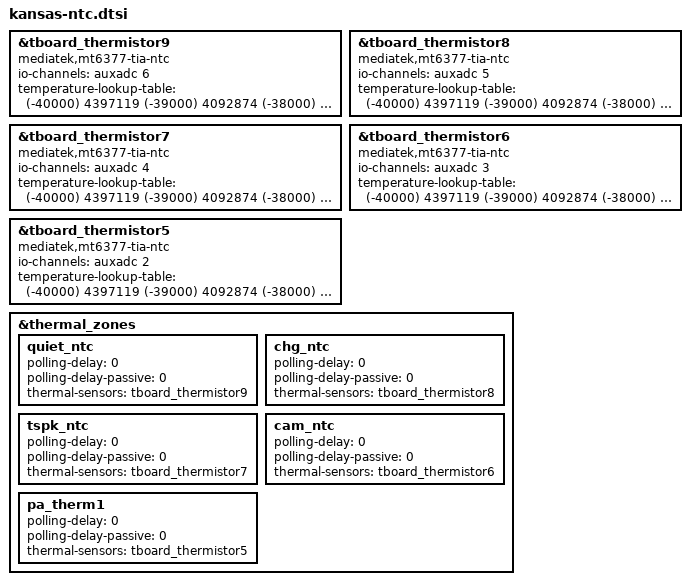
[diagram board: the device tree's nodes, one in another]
/*[TN.NJDC] ntc overlay file.start*/
&tboard_thermistor9 {
	compatible = "mediatek,mt6377-tia-ntc";
	io-channels = <&auxadc 6>;
	io-channel-names = "QUIET_NTC";
	#thermal-sensor-cells = <0>;
	temperature-lookup-table = <
		(-40000) 4397119
		(-39000) 4092874
		(-38000) 3811717
		(-37000) 3551749
		(-36000) 3311236
		(-35000) 3088599
		(-34000) 2882396
		(-33000) 2691310
		(-32000) 2514137
		(-31000) 2349778
		(-30000) 2197225
		(-29000) 2055558
		(-28000) 1923932
		(-27000) 1801573
		(-26000) 1687773
		(-25000) 1581881
		(-24000) 1483100
		(-23000) 1391113
		(-22000) 1305413
		(-21000) 1225531
		(-20000) 1151037
		(-19000) 1081535
		(-18000) 1016661
		(-17000) 956080
		(-16000) 899481
		(-15000) 846579
		(-14000) 797111
		(-13000) 750834
		(-12000) 707524
		(-11000) 666972
		(-10000) 628988
		(-9000) 593342
		(-8000) 559931
		(-7000) 528602
		(-6000) 499212
		(-5000) 471632
		(-4000) 445772
		(-3000) 421480
		(-2000) 398652
		(-1000) 377193
		0 357012
		1000 338006
		2000 320122
		3000 303287
		4000 287434
		5000 272500
		6000 258426
		7000 245160
		8000 232649
		9000 220847
		10000 209710
		11000 199196
		12000 189268
		13000 179890
		14000 171027
		15000 162651
		16000 154726
		17000 147232
		18000 140142
		19000 133432
		20000 127080
		21000 121066
		22000 115368
		23000 109970
		24000 104852
		25000 100000
		26000 95398
		27000 91032
		28000 86889
		29000 82956
		30000 79222
		31000 75675
		32000 72306
		33000 69104
		34000 66061
		35000 63167
		36000 60415
		37000 57797
		38000 55306
		39000 52934
		40000 50677
		41000 48528
		42000 46482
		43000 44533
		44000 42675
		45000 40904
		46000 39213
		47000 37601
		48000 36063
		49000 34595
		50000 33195
		51000 31859
		52000 30584
		53000 29366
		54000 28203
		55000 27091
		56000 26028
		57000 25013
		58000 24042
		59000 23113
		60000 22224
		61000 21374
		62000 20560
		63000 19782
		64000 19036
		65000 18322
		66000 17640
		67000 16986
		68000 16360
		69000 15759
		70000 15184
		71000 14631
		72000 14100
		73000 13591
		74000 13103
		75000 12635
		76000 12187
		77000 11756
		78000 11343
		79000 10946
		80000 10565
		81000 10199
		82000 9847
		83000 9509
		84000 9184
		85000 8872
		86000 8572
		87000 8283
		88000 8005
		89000 7738
		90000 7481
		91000 7234
		92000 6997
		93000 6769
		94000 6548
		95000 6337
		96000 6132
		97000 5934
		98000 5744
		99000 5561
		100000 5384
		101000 5214
		102000 5051
		103000 4893
		104000 4741
		105000 4594
		106000 4453
		107000 4316
		108000 4184
		109000 4057
		110000 3934
		111000 3816
		112000 3701
		113000 3591
		114000 3484
		115000 3380
		116000 3281
		117000 3185
		118000 3093
		119000 3003
		120000 2916
		121000 2832
		122000 2751
		123000 2672
		124000 2596
		125000 2522>;
};
&tboard_thermistor8 {
	compatible = "mediatek,mt6377-tia-ntc";
	io-channels = <&auxadc 5>;
	io-channel-names = "CHG_NTC";
	#thermal-sensor-cells = <0>;
	temperature-lookup-table = <
		(-40000) 4397119
		(-39000) 4092874
		(-38000) 3811717
		(-37000) 3551749
		(-36000) 3311236
		(-35000) 3088599
		(-34000) 2882396
		(-33000) 2691310
		(-32000) 2514137
		(-31000) 2349778
		(-30000) 2197225
		(-29000) 2055558
		(-28000) 1923932
		(-27000) 1801573
		(-26000) 1687773
		(-25000) 1581881
		(-24000) 1483100
		(-23000) 1391113
		(-22000) 1305413
		(-21000) 1225531
		(-20000) 1151037
		(-19000) 1081535
		(-18000) 1016661
		(-17000) 956080
		(-16000) 899481
		(-15000) 846579
		(-14000) 797111
		(-13000) 750834
		(-12000) 707524
		(-11000) 666972
		(-10000) 628988
		(-9000) 593342
		(-8000) 559931
		(-7000) 528602
		(-6000) 499212
		(-5000) 471632
		(-4000) 445772
		(-3000) 421480
		(-2000) 398652
		(-1000) 377193
		0 357012
		1000 338006
		2000 320122
		3000 303287
		4000 287434
		5000 272500
		6000 258426
		7000 245160
		8000 232649
		9000 220847
		10000 209710
		11000 199196
		12000 189268
		13000 179890
		14000 171027
		15000 162651
		16000 154726
		17000 147232
		18000 140142
		19000 133432
		20000 127080
		21000 121066
		22000 115368
		23000 109970
		24000 104852
		25000 100000
		26000 95398
		27000 91032
		28000 86889
		29000 82956
		30000 79222
		31000 75675
		32000 72306
		33000 69104
		34000 66061
		35000 63167
		36000 60415
		37000 57797
		38000 55306
		39000 52934
		40000 50677
		41000 48528
		42000 46482
		43000 44533
		44000 42675
		45000 40904
		46000 39213
		47000 37601
		48000 36063
		49000 34595
		50000 33195
		51000 31859
		52000 30584
		53000 29366
		54000 28203
		55000 27091
		56000 26028
		57000 25013
		58000 24042
		59000 23113
		60000 22224
		61000 21374
		62000 20560
		63000 19782
		64000 19036
		65000 18322
		66000 17640
		67000 16986
		68000 16360
		69000 15759
		70000 15184
		71000 14631
		72000 14100
		73000 13591
		74000 13103
		75000 12635
		76000 12187
		77000 11756
		78000 11343
		79000 10946
		80000 10565
		81000 10199
		82000 9847
		83000 9509
		84000 9184
		85000 8872
		86000 8572
		87000 8283
		88000 8005
		89000 7738
		90000 7481
		91000 7234
		92000 6997
		93000 6769
		94000 6548
		95000 6337
		96000 6132
		97000 5934
		98000 5744
		99000 5561
		100000 5384
		101000 5214
		102000 5051
		103000 4893
		104000 4741
		105000 4594
		106000 4453
		107000 4316
		108000 4184
		109000 4057
		110000 3934
		111000 3816
		112000 3701
		113000 3591
		114000 3484
		115000 3380
		116000 3281
		117000 3185
		118000 3093
		119000 3003
		120000 2916
		121000 2832
		122000 2751
		123000 2672
		124000 2596
		125000 2522>;
};
&tboard_thermistor7 {
	compatible = "mediatek,mt6377-tia-ntc";
	io-channels = <&auxadc 4>;
	io-channel-names = "SPK_NTC";
	#thermal-sensor-cells = <0>;
	temperature-lookup-table = <
		(-40000) 4397119
		(-39000) 4092874
		(-38000) 3811717
		(-37000) 3551749
		(-36000) 3311236
		(-35000) 3088599
		(-34000) 2882396
		(-33000) 2691310
		(-32000) 2514137
		(-31000) 2349778
		(-30000) 2197225
		(-29000) 2055558
		(-28000) 1923932
		(-27000) 1801573
		(-26000) 1687773
		(-25000) 1581881
		(-24000) 1483100
		(-23000) 1391113
		(-22000) 1305413
		(-21000) 1225531
		(-20000) 1151037
		(-19000) 1081535
		(-18000) 1016661
		(-17000) 956080
		(-16000) 899481
		(-15000) 846579
		(-14000) 797111
		(-13000) 750834
		(-12000) 707524
		(-11000) 666972
		(-10000) 628988
		(-9000) 593342
		(-8000) 559931
		(-7000) 528602
		(-6000) 499212
		(-5000) 471632
		(-4000) 445772
		(-3000) 421480
		(-2000) 398652
		(-1000) 377193
		0 357012
		1000 338006
		2000 320122
		3000 303287
		4000 287434
		5000 272500
		6000 258426
		7000 245160
		8000 232649
		9000 220847
		10000 209710
		11000 199196
		12000 189268
		13000 179890
		14000 171027
		15000 162651
		16000 154726
		17000 147232
		18000 140142
		19000 133432
		20000 127080
		21000 121066
		22000 115368
		23000 109970
		24000 104852
		25000 100000
		26000 95398
		27000 91032
		28000 86889
		29000 82956
		30000 79222
		31000 75675
		32000 72306
		33000 69104
		34000 66061
		35000 63167
		36000 60415
		37000 57797
		38000 55306
		39000 52934
		40000 50677
		41000 48528
		42000 46482
		43000 44533
		44000 42675
		45000 40904
		46000 39213
		47000 37601
		48000 36063
		49000 34595
		50000 33195
		51000 31859
		52000 30584
		53000 29366
		54000 28203
		55000 27091
		56000 26028
		57000 25013
		58000 24042
		59000 23113
		60000 22224
		61000 21374
		62000 20560
		63000 19782
		64000 19036
		65000 18322
		66000 17640
		67000 16986
		68000 16360
		69000 15759
		70000 15184
		71000 14631
		72000 14100
		73000 13591
		74000 13103
		75000 12635
		76000 12187
		77000 11756
		78000 11343
		79000 10946
		80000 10565
		81000 10199
		82000 9847
		83000 9509
		84000 9184
		85000 8872
		86000 8572
		87000 8283
		88000 8005
		89000 7738
		90000 7481
		91000 7234
		92000 6997
		93000 6769
		94000 6548
		95000 6337
		96000 6132
		97000 5934
		98000 5744
		99000 5561
		100000 5384
		101000 5214
		102000 5051
		103000 4893
		104000 4741
		105000 4594
		106000 4453
		107000 4316
		108000 4184
		109000 4057
		110000 3934
		111000 3816
		112000 3701
		113000 3591
		114000 3484
		115000 3380
		116000 3281
		117000 3185
		118000 3093
		119000 3003
		120000 2916
		121000 2832
		122000 2751
		123000 2672
		124000 2596
		125000 2522>;
};
&tboard_thermistor6 {
	compatible = "mediatek,mt6377-tia-ntc";
	io-channels = <&auxadc 3>;
	io-channel-names = "CAM_NTC";
	#thermal-sensor-cells = <0>;
	temperature-lookup-table = <
		(-40000) 4397119
		(-39000) 4092874
		(-38000) 3811717
		(-37000) 3551749
		(-36000) 3311236
		(-35000) 3088599
		(-34000) 2882396
		(-33000) 2691310
		(-32000) 2514137
		(-31000) 2349778
		(-30000) 2197225
		(-29000) 2055558
		(-28000) 1923932
		(-27000) 1801573
		(-26000) 1687773
		(-25000) 1581881
		(-24000) 1483100
		(-23000) 1391113
		(-22000) 1305413
		(-21000) 1225531
		(-20000) 1151037
		(-19000) 1081535
		(-18000) 1016661
		(-17000) 956080
		(-16000) 899481
		(-15000) 846579
		(-14000) 797111
		(-13000) 750834
		(-12000) 707524
		(-11000) 666972
		(-10000) 628988
		(-9000) 593342
		(-8000) 559931
		(-7000) 528602
		(-6000) 499212
		(-5000) 471632
		(-4000) 445772
		(-3000) 421480
		(-2000) 398652
		(-1000) 377193
		0 357012
		1000 338006
		2000 320122
		3000 303287
		4000 287434
		5000 272500
		6000 258426
		7000 245160
		8000 232649
		9000 220847
		10000 209710
		11000 199196
		12000 189268
		13000 179890
		14000 171027
		15000 162651
		16000 154726
		17000 147232
		18000 140142
		19000 133432
		20000 127080
		21000 121066
		22000 115368
		23000 109970
		24000 104852
		25000 100000
		26000 95398
		27000 91032
		28000 86889
		29000 82956
		30000 79222
		31000 75675
		32000 72306
		33000 69104
		34000 66061
		35000 63167
		36000 60415
		37000 57797
		38000 55306
		39000 52934
		40000 50677
		41000 48528
		42000 46482
		43000 44533
		44000 42675
		45000 40904
		46000 39213
		47000 37601
		48000 36063
		49000 34595
		50000 33195
		51000 31859
		52000 30584
		53000 29366
		54000 28203
		55000 27091
		56000 26028
		57000 25013
		58000 24042
		59000 23113
		60000 22224
		61000 21374
		62000 20560
		63000 19782
		64000 19036
		65000 18322
		66000 17640
		67000 16986
		68000 16360
		69000 15759
		70000 15184
		71000 14631
		72000 14100
		73000 13591
		74000 13103
		75000 12635
		76000 12187
		77000 11756
		78000 11343
		79000 10946
		80000 10565
		81000 10199
		82000 9847
		83000 9509
		84000 9184
		85000 8872
		86000 8572
		87000 8283
		88000 8005
		89000 7738
		90000 7481
		91000 7234
		92000 6997
		93000 6769
		94000 6548
		95000 6337
		96000 6132
		97000 5934
		98000 5744
		99000 5561
		100000 5384
		101000 5214
		102000 5051
		103000 4893
		104000 4741
		105000 4594
		106000 4453
		107000 4316
		108000 4184
		109000 4057
		110000 3934
		111000 3816
		112000 3701
		113000 3591
		114000 3484
		115000 3380
		116000 3281
		117000 3185
		118000 3093
		119000 3003
		120000 2916
		121000 2832
		122000 2751
		123000 2672
		124000 2596
		125000 2522>;
};
&tboard_thermistor5 {
	compatible = "mediatek,mt6377-tia-ntc";
	io-channels = <&auxadc 2>;
	io-channel-names = "WCN_NTC";
	#thermal-sensor-cells = <0>;
	temperature-lookup-table = <
		(-40000) 4397119
		(-39000) 4092874
		(-38000) 3811717
		(-37000) 3551749
		(-36000) 3311236
		(-35000) 3088599
		(-34000) 2882396
		(-33000) 2691310
		(-32000) 2514137
		(-31000) 2349778
		(-30000) 2197225
		(-29000) 2055558
		(-28000) 1923932
		(-27000) 1801573
		(-26000) 1687773
		(-25000) 1581881
		(-24000) 1483100
		(-23000) 1391113
		(-22000) 1305413
		(-21000) 1225531
		(-20000) 1151037
		(-19000) 1081535
		(-18000) 1016661
		(-17000) 956080
		(-16000) 899481
		(-15000) 846579
		(-14000) 797111
		(-13000) 750834
		(-12000) 707524
		(-11000) 666972
		(-10000) 628988
		(-9000) 593342
		(-8000) 559931
		(-7000) 528602
		(-6000) 499212
		(-5000) 471632
		(-4000) 445772
		(-3000) 421480
		(-2000) 398652
		(-1000) 377193
		0 357012
		1000 338006
		2000 320122
		3000 303287
		4000 287434
		5000 272500
		6000 258426
		7000 245160
		8000 232649
		9000 220847
		10000 209710
		11000 199196
		12000 189268
		13000 179890
		14000 171027
		15000 162651
		16000 154726
		17000 147232
		18000 140142
		19000 133432
		20000 127080
		21000 121066
		22000 115368
		23000 109970
		24000 104852
		25000 100000
		26000 95398
		27000 91032
		28000 86889
		29000 82956
		30000 79222
		31000 75675
		32000 72306
		33000 69104
		34000 66061
		35000 63167
		36000 60415
		37000 57797
		38000 55306
		39000 52934
		40000 50677
		41000 48528
		42000 46482
		43000 44533
		44000 42675
		45000 40904
		46000 39213
		47000 37601
		48000 36063
		49000 34595
		50000 33195
		51000 31859
		52000 30584
		53000 29366
		54000 28203
		55000 27091
		56000 26028
		57000 25013
		58000 24042
		59000 23113
		60000 22224
		61000 21374
		62000 20560
		63000 19782
		64000 19036
		65000 18322
		66000 17640
		67000 16986
		68000 16360
		69000 15759
		70000 15184
		71000 14631
		72000 14100
		73000 13591
		74000 13103
		75000 12635
		76000 12187
		77000 11756
		78000 11343
		79000 10946
		80000 10565
		81000 10199
		82000 9847
		83000 9509
		84000 9184
		85000 8872
		86000 8572
		87000 8283
		88000 8005
		89000 7738
		90000 7481
		91000 7234
		92000 6997
		93000 6769
		94000 6548
		95000 6337
		96000 6132
		97000 5934
		98000 5744
		99000 5561
		100000 5384
		101000 5214
		102000 5051
		103000 4893
		104000 4741
		105000 4594
		106000 4453
		107000 4316
		108000 4184
		109000 4057
		110000 3934
		111000 3816
		112000 3701
		113000 3591
		114000 3484
		115000 3380
		116000 3281
		117000 3185
		118000 3093
		119000 3003
		120000 2916
		121000 2832
		122000 2751
		123000 2672
		124000 2596
		125000 2522>;
};

&thermal_zones {
	quiet_ntc: quiet_ntc {
		polling-delay = <0>; /* milliseconds */
		polling-delay-passive = <0>; /* milliseconds */
		thermal-sensors = <&tboard_thermistor9>;
	};
	chg_ntc: chg_ntc {
		polling-delay = <0>; /* milliseconds */
		polling-delay-passive = <0>; /* milliseconds */
		thermal-sensors = <&tboard_thermistor8>;
	};
	tspk_ntc: tspk_ntc {
		polling-delay = <0>; /* milliseconds */
		polling-delay-passive = <0>; /* milliseconds */
		thermal-sensors = <&tboard_thermistor7>;
	};
	cam_ntc: cam_ntc {
		polling-delay = <0>; /* milliseconds */
		polling-delay-passive = <0>; /* milliseconds */
		thermal-sensors = <&tboard_thermistor6>;
	};
	pa_therm1: pa_therm1 {
		polling-delay = <0>; /* milliseconds */
		polling-delay-passive = <0>; /* milliseconds */
		thermal-sensors = <&tboard_thermistor5>;
	};
};
/*[TN.NJDC] ntc overlay file.end*/
